# ing920 register map
Vendor: INGChips; Series: ing920xx; File version: 1.0
CPU: CM3 r2p1, little endian, no MPU, no FPU, 2 interrupt priority bits
Registers are 32-bit, read-write, reset 0x0 unless marked. A register's access mark holds for its fields unless they carry their own. Offsets are from the block's base; [hi:lo] are bit positions; {n}, {i} and the like mark numbered series.

## pwm
Base 0x40005000
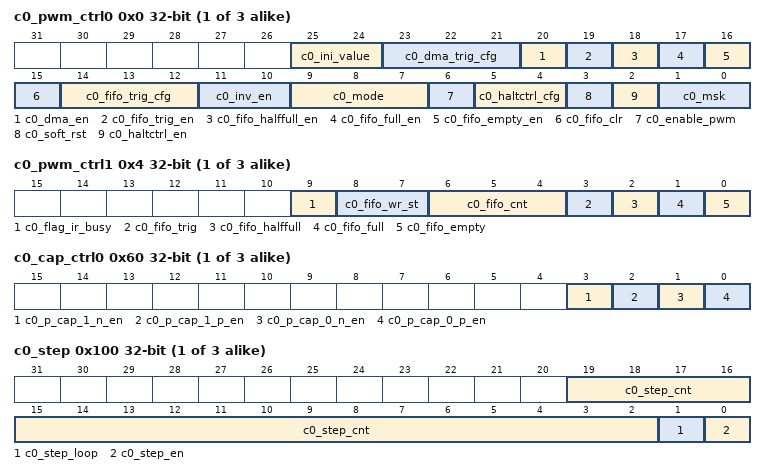
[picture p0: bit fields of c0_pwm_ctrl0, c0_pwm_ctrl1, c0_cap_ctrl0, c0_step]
{0x0+0x20*i} c{i}_pwm_ctrl0 (i=0..2) — reg description:
  [25:24] c{i}_ini_value — reg description:
  [23:21] c{i}_dma_trig_cfg — reg description:
  [20] c{i}_dma_en — reg description:
  [19] c{i}_fifo_trig_en — reg description:
  [18] c{i}_fifo_halffull_en — reg description:
  [17] c{i}_fifo_full_en — reg description:
  [16] c{i}_fifo_empty_en — reg description:
  [15] c{i}_fifo_clr — reg description:
  [14:12] c{i}_fifo_trig_cfg — reg description:
  [11:10] c{i}_inv_en — reg description:
  [9:7] c{i}_mode — reg description:
  [6] c{i}_enable_pwm — reg description:
  [5:4] c{i}_haltctrl_cfg — reg description:
  [3] c{i}_soft_rst — reg description:
  [2] c{i}_haltctrl_en — reg description:
  [1:0] c{i}_msk — reg description:
{0x4+0x20*i} c{i}_pwm_ctrl1 (i=0..2) — reg description:
  [9] c{i}_flag_ir_busy — reg description:
  [8:7] c{i}_fifo_wr_st — reg description:
  [6:4] c{i}_fifo_cnt — reg description:
  [3] c{i}_fifo_trig — reg description:
  [2] c{i}_fifo_halffull — reg description:
  [1] c{i}_fifo_full — reg description:
  [0] c{i}_fifo_empty — reg description:
{0x10+0x20*i} c{i}_pwm_ctrl2 (i=0..2) — reg description:
  [19:0] c{i}_pera_th
{0x14+0x20*i} c{i}_pwm_ctrl3 (i=0..2) — reg description:
  [19:0] c{i}_high_th
{0x18+0x20*i} c{i}_pwm_ctrl4 (i=0..2) — reg description:
  [19:0] c{i}_dzone_th
{0x1C+0x20*i} c{i}_pwm_ctrl5 (i=0..2) — reg description:
  [19:0] c{i}_dma_data
{0x60+0x10*i} c{i}_cap_ctrl0 (i=0..2) — reg description:
  [3] c{i}_p_cap_1_n_en — reg description:
  [2] c{i}_p_cap_1_p_en — reg description:
  [1] c{i}_p_cap_0_n_en — reg description:
  [0] c{i}_p_cap_0_p_en — reg description:
{0x64+0x10*i} c{i}_cap_ctrl1 (i=0..2) — reg description:
  [31:0] c{i}_cap_data
0x90 cap_cnt_en — reg description:
  [0] cap_cnt_en
0x94 cap_cnt — reg description:
{0x100+0x10*i} c{i}_step (i=0..2) — reg description:
  [19:2] c{i}_step_cnt — reg description:
  [1] c{i}_step_loop — reg description:
  [0] c{i}_step_en — reg description:
{0x104+0x10*i} c{i}_step1 (i=0..2) — reg description:
  [19:0] c{i}_step_target

## sadc
Base 0x4000F000
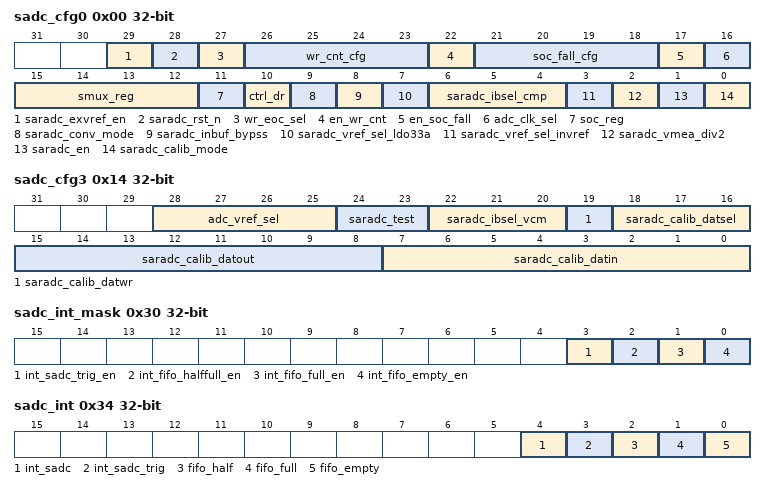
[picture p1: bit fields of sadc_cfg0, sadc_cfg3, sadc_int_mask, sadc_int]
0x00 sadc_cfg0 — reg description:
  [29] saradc_exvref_en — reg description:
  [28] saradc_rst_n — reg description:
  [27] wr_eoc_sel — reg description:
  [26:23] wr_cnt_cfg — reg description:
  [22] en_wr_cnt — reg description:
  [21:18] soc_fall_cfg — reg description:
  [17] en_soc_fall — reg description:
  [16] adc_clk_sel — reg description:
  [15:12] smux_reg — reg description:
  [11] soc_reg — reg description:
  [10] ctrl_dr — reg description:
  [9] saradc_conv_mode — reg description:
  [8] saradc_inbuf_bypss — reg description:
  [7] saradc_vref_sel_ldo33a — reg description:
  [6:4] saradc_ibsel_cmp — reg description:
  [3] saradc_vref_sel_invref — reg description:
  [2] saradc_vmea_div2 — reg description:
  [1] saradc_en — reg description:
  [0] saradc_calib_mode — reg description:
0x04 sadc_cfg1 — reg description:
  [31:0] loop_delay
0x08 sadc_cfg2 — reg description:
  [0] adc_ctrl_mode
0x0C sadc_data — reg description:
  [15:0] sadc_data
0x10 sadc_status0 — reg description:
0x14 sadc_cfg3 — reg description:
  [28:25] adc_vref_sel — reg description:
  [24:23] saradc_test — reg description:
  [22:20] saradc_ibsel_vcm — reg description:
  [19] saradc_calib_datwr — reg description:
  [18:16] saradc_calib_datsel — reg description:
  [15:8] saradc_calib_datout — reg description:
  [7:0] saradc_calib_datin — reg description:
0x30 sadc_int_mask — reg description:
  [3] int_sadc_trig_en — reg description:
  [2] int_fifo_halffull_en — reg description:
  [1] int_fifo_full_en — reg description:
  [0] int_fifo_empty_en — reg description:
0x34 sadc_int — reg description:
  [4] int_sadc — reg description:
  [3] int_sadc_trig — reg description:
  [2] fifo_half — reg description:
  [1] fifo_full — reg description:
  [0] fifo_empty — reg description:
